VERSION ""

NS_ :

BS_:

BU_: CAR ANY ACTUATOR SAFETY

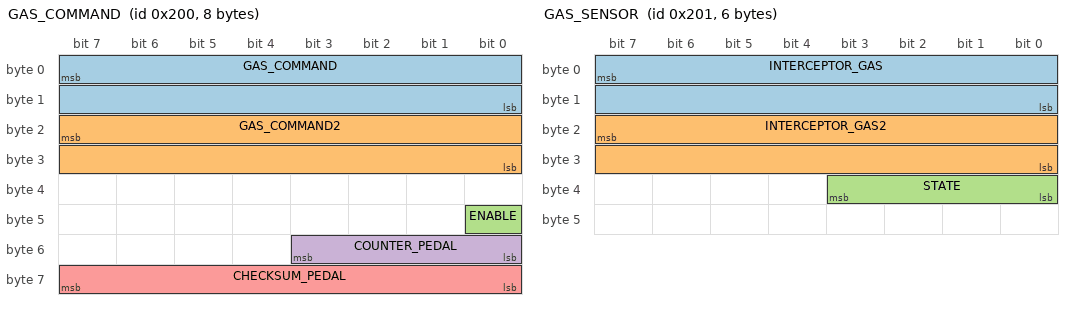
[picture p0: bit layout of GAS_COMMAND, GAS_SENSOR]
BO_ 512 GAS_COMMAND: 8 SAFETY
 SG_ GAS_COMMAND : 7|16@0+ (1,0) [0|1] "" ACTUATOR
 SG_ GAS_COMMAND2 : 23|16@0+ (1,0) [0|1] "" ACTUATOR
 SG_ ENABLE : 40|1@0+ (1,0) [0|1] "" ACTUATOR
 SG_ COUNTER_PEDAL : 51|4@0+ (1,0) [0|15] "" ACTUATOR
 SG_ CHECKSUM_PEDAL : 63|8@0+ (1,0) [0|255] "" ACTUATOR

BO_ 513 GAS_SENSOR: 6 ACTUATOR
 SG_ INTERCEPTOR_GAS : 7|16@0+ (1,0) [0|1] "" SAFETY
 SG_ INTERCEPTOR_GAS2 : 23|16@0+ (1,0) [0|1] "" SAFETY
 SG_ STATE : 35|4@0+ (1,0) [0|15] "" SAFETY

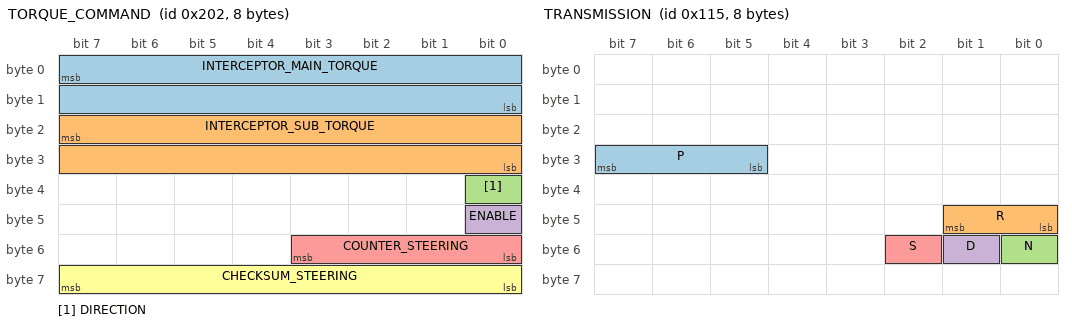
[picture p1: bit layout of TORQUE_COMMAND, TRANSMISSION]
BO_ 514 TORQUE_COMMAND: 8 SAFETY
 SG_ INTERCEPTOR_MAIN_TORQUE : 7|16@0+ (1,0) [0|1] "" ACTUATOR
 SG_ INTERCEPTOR_SUB_TORQUE : 23|16@0+ (1,0) [0|1] "" ACTUATOR
 SG_ DIRECTION : 32|1@0+ (1,0) [0|1] "" ACTUATOR
 SG_ ENABLE : 40|1@0+ (1,0) [0|1] "" ACTUATOR
 SG_ COUNTER_STEERING : 51|4@0+ (1,0) [0|15] "" ACTUATOR
 SG_ CHECKSUM_STEERING : 63|8@0+ (1,0) [0|255] "" ACTUATOR

BO_ 528 WHEEL_SPEED: 8 CAR
 SG_ WHEELSPEED_F : 7|16@0+ (0.0088,-0.0704) [0|16777215] "kph" SAFETY
 SG_ WHEELSPEED_B : 23|16@0+ (0.0011,-0.0704) [0|65535] "kph" SAFETY

BO_ 277 TRANSMISSION: 8 CAR
 SG_ P : 31|3@0+ (1,0) [0|1] "" SAFETY
 SG_ R : 41|2@0+ (1,0) [0|1] "" SAFETY
 SG_ N : 48|1@0+ (1,0) [0|1] "" SAFETY
 SG_ D : 49|1@0+ (1,0) [0|1] "" SAFETY
 SG_ S : 50|1@0+ (1,0) [0|1] "" SAFETY

BO_ 1296 METER_CLUSTER: 8 CAR
 SG_ HANDBRAKE_ENGAGED : 40|1@0+ (1,0) [0|1] "" SAFETY
 SG_ SEAT_BELT_WARNING : 48|1@0+ (1,0) [0|1] "" SAFETY

BO_ 257 BRAKE_PEDAL: 8 CAR
 SG_ BRAKE_ENGAGED : 56|1@0+ (1,0) [0|1] "" SAFETY

BO_ 753 STEERING_TORQUE: 8 CAR
 SG_ MAIN_TORQUE : 0|5@1+ (1,0) [0|31] "" SAFETY

BO_ 419 STEERING_ANGLE_SENSOR: 8 CAR
 SG_ SUB_TORQUE : 48|5@1+ (1,0) [0|31] "" SAFETY
 SG_ STEER_ANGLE : 37|14@0+ (0.04239284,0) [0|16383] "" SAFETY

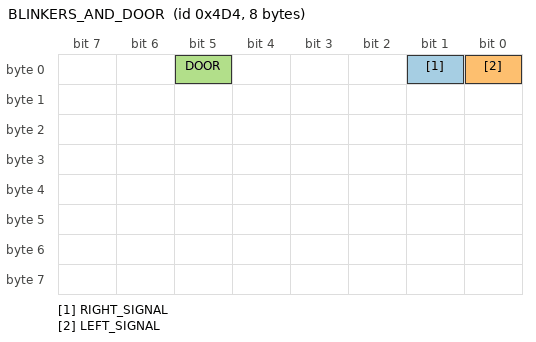
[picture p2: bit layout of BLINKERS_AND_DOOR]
BO_ 1236 BLINKERS_AND_DOOR: 8 CAR
 SG_ RIGHT_SIGNAL : 1|1@0+ (1,0) [0|1] "" SAFETY
 SG_ LEFT_SIGNAL : 0|1@0+ (1,0) [0|1] "" SAFETY
 SG_ DOOR : 5|1@0+ (1,0) [0|1] "" SAFETY

BO_ 625 GAS_PEDAL: 8 CAR
 SG_ APPS_1 : 48|8@1+ (0.003937,0) [0|255] "" SAFETY
 SG_ APPS_2 : 8|8@1+ (0.003937,-0.0157) [0|255] "" SAFETY

BO_ 1263 BRAKE_PEDAL_2: 8 CAR
 SG_ BRAKE_2 : 14|1@0+ (1,0) [0|1] "" SAFETY

BO_ 1827 IGNITION: 8 CAR
 SG_ IGNITION : 16|1@0+ (1,0) [0|1] "" SAFETY

CM_ SG_ 1236 RIGHT_BLINKER "Flickers";
CM_ SG_ 1236 LEFT_BLINKER "Flickers";
